# MSS_IOMUX_IOMUX_53100000h register map
Vendor: Texas Instruments
Peripheral module from a debugger description file (folder AM263X).
Registers are 32-bit, read-write, reset values left out (the file's numbers can be read two ways) unless marked. A register's access mark holds for its fields unless they carry their own. Offsets are as the file gives them; lines under a group give offsets from that group; [hi:lo] are bit positions; {n}, {i} and the like mark numbered series; 'fields as' and 'values as' point back to an identical list; <NAME> marks a mode.

## IOMUX
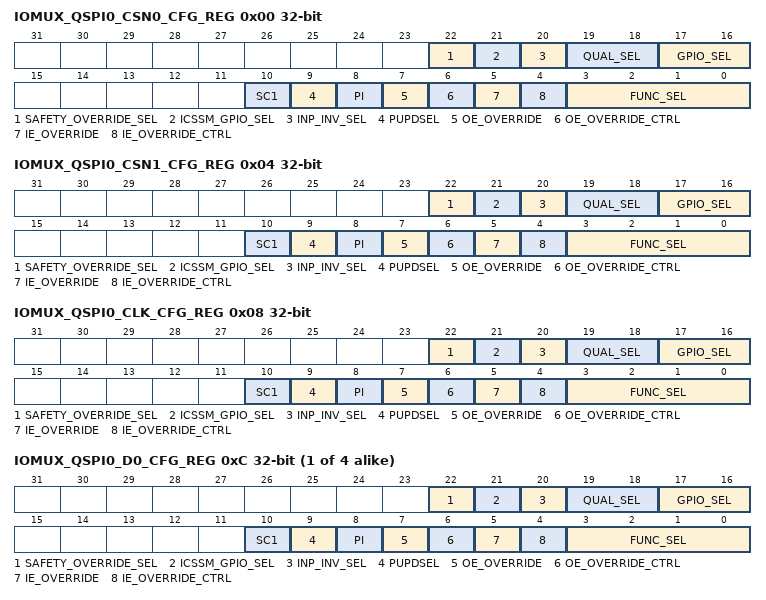
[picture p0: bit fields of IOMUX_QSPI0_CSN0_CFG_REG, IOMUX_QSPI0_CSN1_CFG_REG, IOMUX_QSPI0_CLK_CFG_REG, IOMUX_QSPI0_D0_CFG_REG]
0x00 IOMUX_QSPI0_CSN0_CFG_REG — QSPI0_CSn0 IO config register.
  [22] SAFETY_OVERRIDE_SEL — mux Select Value to choose between Actual IO pad input and Safety override mux output1 Safety override mux output is selected0 Actual IO pad input is selected
  [21] ICSSM_GPIO_SEL — mux Select Value to choose between ICSSM_GPIO and normal GPIO 1 ICSSM_GPIO is selected0 Normal GPIO is selected
  [20] INP_INV_SEL — Select Value for chosing inverted version of PAD input for chip:0 : Non Inverted1 : Inverted
  [19:18] QUAL_SEL — Select Value for chosing input qualifer type for PAD.00 : Sync, 01 : 3 Sample qual 10 : 6 Samples qual 11 : Async
  [17:16] GPIO_SEL — R5F CPU ownership select for GPIO.0 : GPO0, 1 :GPO1,2 : GPO2, 3:GPO3
  [10] SC1 — IO Slew Rate Control :0 : higher slew rate.1:Lower slew rate.
  [9] PUPDSEL — Internal Pull Resistor Direction Control bit0:Pull-down Resistor1:Pull-up Resistor
  [8] PI — Pull Inhibit/Pull Disable 0 -- Enable 1- Disable
  [7] OE_OVERRIDE — Active Low Output Override
  [6] OE_OVERRIDE_CTRL — Output Override Control bit (Active Low)This bit provides a software override for the default OE_N/GZ hardware control.0:Enable pad input override1:Disable pad input override
  [5] IE_OVERRIDE — Input Override (Active Low)0:Override pad input signal to 0 (LOW)1:Override pad input signal to 1 (HIGH)
  [4] IE_OVERRIDE_CTRL — Input Override (Active Low)0:Override pad input signal to 0 (LOW)1:Override pad input signal to 1 (HIGH) Control : Write 1 to select Active low Input Override value to control IOs IE_N/RXACTIVE_N instead of the control from hardware
  [3:0] FUNC_SEL — Function select
0x04 IOMUX_QSPI0_CSN1_CFG_REG — QSPI0_CSn1 IO config register.
  fields as IOMUX_QSPI0_CSN0_CFG_REG
0x08 IOMUX_QSPI0_CLK_CFG_REG — QSPI0_CLK IO config register.
  fields as IOMUX_QSPI0_CSN0_CFG_REG
{0xC+4i} IOMUX_QSPI0_D{i}_CFG_REG (i=0..3) — QSPI0_D{i} IO config register.
  fields as IOMUX_QSPI0_CSN0_CFG_REG
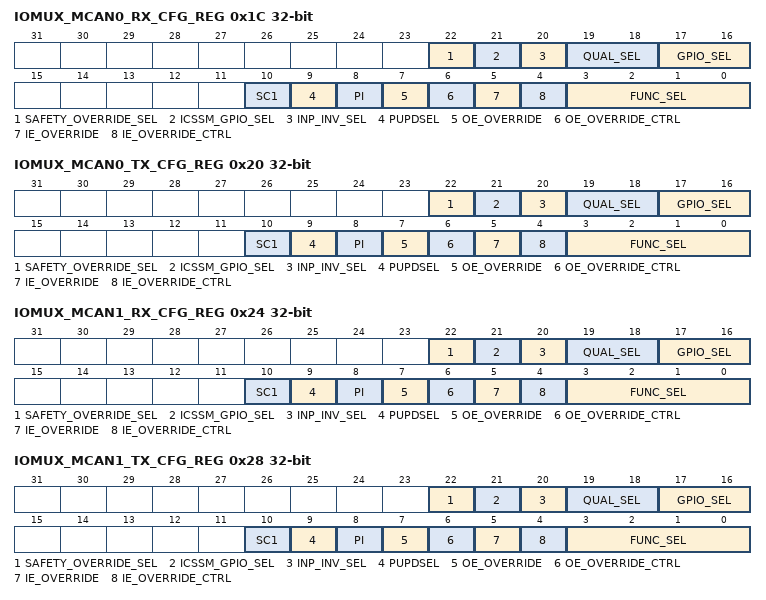
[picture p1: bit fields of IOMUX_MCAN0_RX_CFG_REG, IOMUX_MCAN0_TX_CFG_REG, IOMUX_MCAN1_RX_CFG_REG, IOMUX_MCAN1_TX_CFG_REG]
0x1C IOMUX_MCAN0_RX_CFG_REG — MCAN0_RX IO config register.
  fields as IOMUX_QSPI0_CSN0_CFG_REG
0x20 IOMUX_MCAN0_TX_CFG_REG — MCAN0_TX IO config register.
  fields as IOMUX_QSPI0_CSN0_CFG_REG
0x24 IOMUX_MCAN1_RX_CFG_REG — MCAN1_RX IO config register.
  fields as IOMUX_QSPI0_CSN0_CFG_REG
0x28 IOMUX_MCAN1_TX_CFG_REG — MCAN1_TX IO config register.
  fields as IOMUX_QSPI0_CSN0_CFG_REG
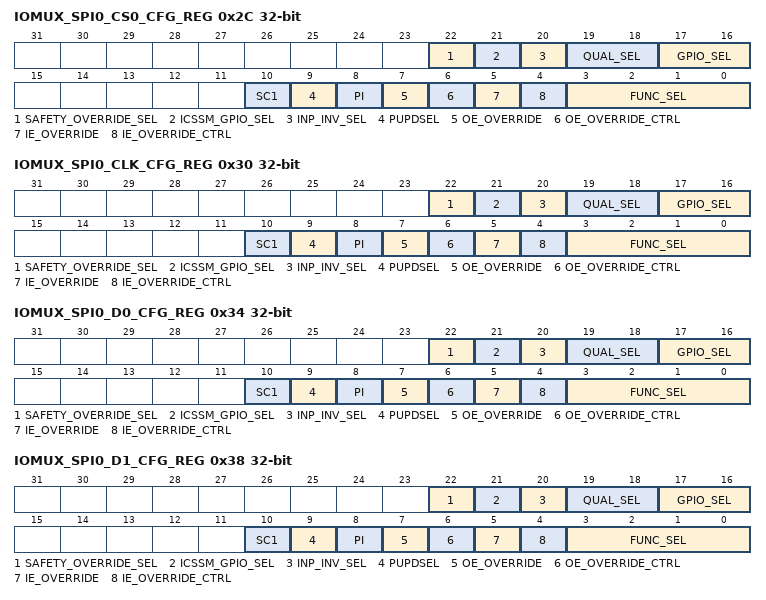
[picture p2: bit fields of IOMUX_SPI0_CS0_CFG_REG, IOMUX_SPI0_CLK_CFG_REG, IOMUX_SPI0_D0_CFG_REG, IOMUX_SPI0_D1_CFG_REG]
0x2C IOMUX_SPI0_CS0_CFG_REG — SPI0_CS0 IO config register.
  fields as IOMUX_QSPI0_CSN0_CFG_REG
0x30 IOMUX_SPI0_CLK_CFG_REG — SPI0_CLK IO config register.
  fields as IOMUX_QSPI0_CSN0_CFG_REG
0x34 IOMUX_SPI0_D0_CFG_REG — SPI0_D0 IO config register.
  fields as IOMUX_QSPI0_CSN0_CFG_REG
0x38 IOMUX_SPI0_D1_CFG_REG — SPI0_D1 IO config register.
  fields as IOMUX_QSPI0_CSN0_CFG_REG
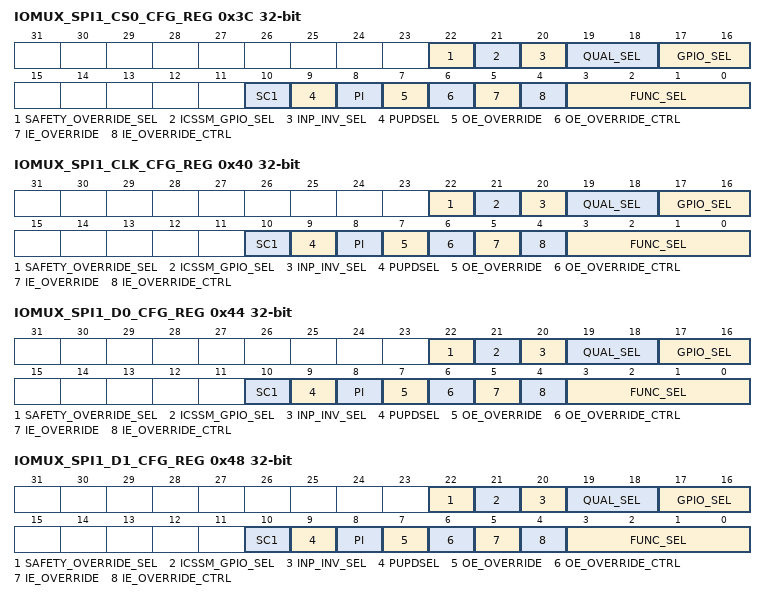
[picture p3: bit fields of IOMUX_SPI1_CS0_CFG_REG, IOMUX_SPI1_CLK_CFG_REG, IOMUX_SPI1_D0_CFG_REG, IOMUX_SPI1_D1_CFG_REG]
0x3C IOMUX_SPI1_CS0_CFG_REG — SPI1_CS0 IO config register.
  fields as IOMUX_QSPI0_CSN0_CFG_REG
0x40 IOMUX_SPI1_CLK_CFG_REG — SPI1_CLK IO config register.
  fields as IOMUX_QSPI0_CSN0_CFG_REG
0x44 IOMUX_SPI1_D0_CFG_REG — SPI1_D0 IO config register.
  fields as IOMUX_QSPI0_CSN0_CFG_REG
0x48 IOMUX_SPI1_D1_CFG_REG — SPI1_D1 IO config register.
  fields as IOMUX_QSPI0_CSN0_CFG_REG
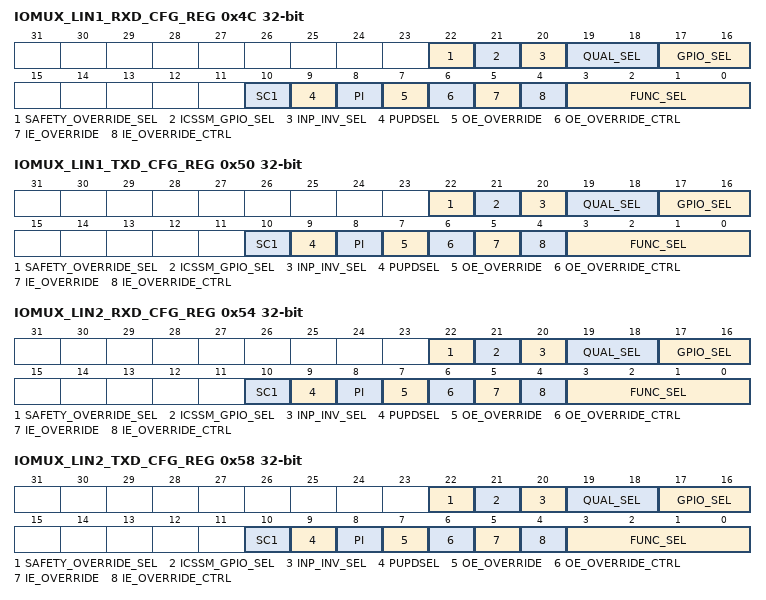
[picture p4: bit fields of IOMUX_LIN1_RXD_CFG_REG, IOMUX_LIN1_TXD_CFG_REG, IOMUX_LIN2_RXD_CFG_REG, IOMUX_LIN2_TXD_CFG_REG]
0x4C IOMUX_LIN1_RXD_CFG_REG — LIN1_RXD IO config register.
  fields as IOMUX_QSPI0_CSN0_CFG_REG
0x50 IOMUX_LIN1_TXD_CFG_REG — LIN1_TXD IO config register.
  fields as IOMUX_QSPI0_CSN0_CFG_REG
0x54 IOMUX_LIN2_RXD_CFG_REG — LIN2_RXD IO config register.
  fields as IOMUX_QSPI0_CSN0_CFG_REG
0x58 IOMUX_LIN2_TXD_CFG_REG — LIN2_TXD IO config register.
  fields as IOMUX_QSPI0_CSN0_CFG_REG
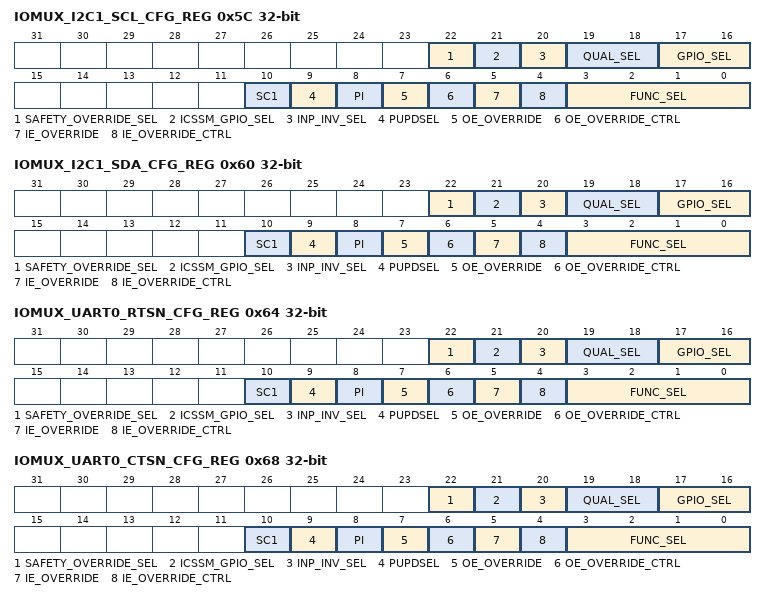
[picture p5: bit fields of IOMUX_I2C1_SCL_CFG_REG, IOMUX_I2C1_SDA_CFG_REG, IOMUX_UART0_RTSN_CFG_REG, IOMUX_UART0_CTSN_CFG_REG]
0x5C IOMUX_I2C1_SCL_CFG_REG — I2C1_SCL IO config register.
  fields as IOMUX_QSPI0_CSN0_CFG_REG
0x60 IOMUX_I2C1_SDA_CFG_REG — I2C1_SDA IO config register.
  fields as IOMUX_QSPI0_CSN0_CFG_REG
0x64 IOMUX_UART0_RTSN_CFG_REG — UART0_RTSn IO config register.
  fields as IOMUX_QSPI0_CSN0_CFG_REG
0x68 IOMUX_UART0_CTSN_CFG_REG — UART0_CTSn IO config register.
  fields as IOMUX_QSPI0_CSN0_CFG_REG
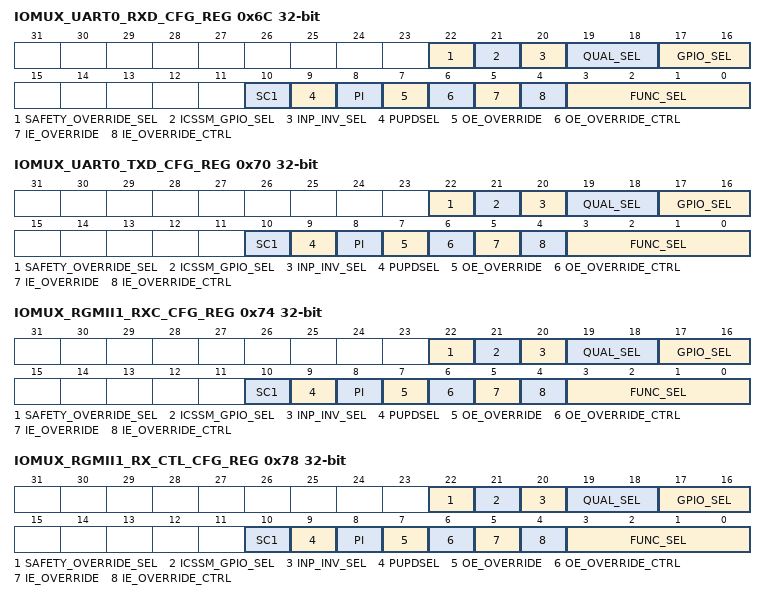
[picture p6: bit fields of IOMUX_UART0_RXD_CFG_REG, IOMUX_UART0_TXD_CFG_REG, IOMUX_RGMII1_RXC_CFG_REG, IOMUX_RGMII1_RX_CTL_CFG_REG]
0x6C IOMUX_UART0_RXD_CFG_REG — UART0_RXD IO config register.
  fields as IOMUX_QSPI0_CSN0_CFG_REG
0x70 IOMUX_UART0_TXD_CFG_REG — UART0_TXD IO config register.
  fields as IOMUX_QSPI0_CSN0_CFG_REG
0x74 IOMUX_RGMII1_RXC_CFG_REG — RGMII1_RXC IO config register.
  fields as IOMUX_QSPI0_CSN0_CFG_REG
0x78 IOMUX_RGMII1_RX_CTL_CFG_REG — RGMII1_RX_CTL IO config register.
  fields as IOMUX_QSPI0_CSN0_CFG_REG
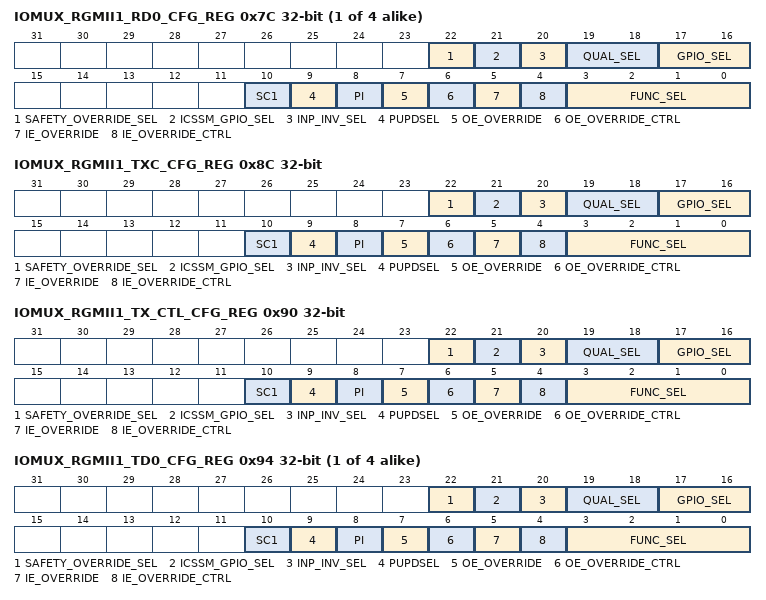
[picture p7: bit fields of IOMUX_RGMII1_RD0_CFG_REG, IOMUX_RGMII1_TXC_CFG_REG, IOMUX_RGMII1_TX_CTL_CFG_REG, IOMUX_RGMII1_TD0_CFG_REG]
{0x7C+4i} IOMUX_RGMII1_RD{i}_CFG_REG (i=0..3) — RGMII1_RD{i} IO config register.
  fields as IOMUX_QSPI0_CSN0_CFG_REG
0x8C IOMUX_RGMII1_TXC_CFG_REG — RGMII1_TXC IO config register.
  fields as IOMUX_QSPI0_CSN0_CFG_REG
0x90 IOMUX_RGMII1_TX_CTL_CFG_REG — RGMII1_TX_CTL IO config register.
  fields as IOMUX_QSPI0_CSN0_CFG_REG
{0x94+4i} IOMUX_RGMII1_TD{i}_CFG_REG (i=0..3) — RGMII1_TD{i} IO config register.
  fields as IOMUX_QSPI0_CSN0_CFG_REG
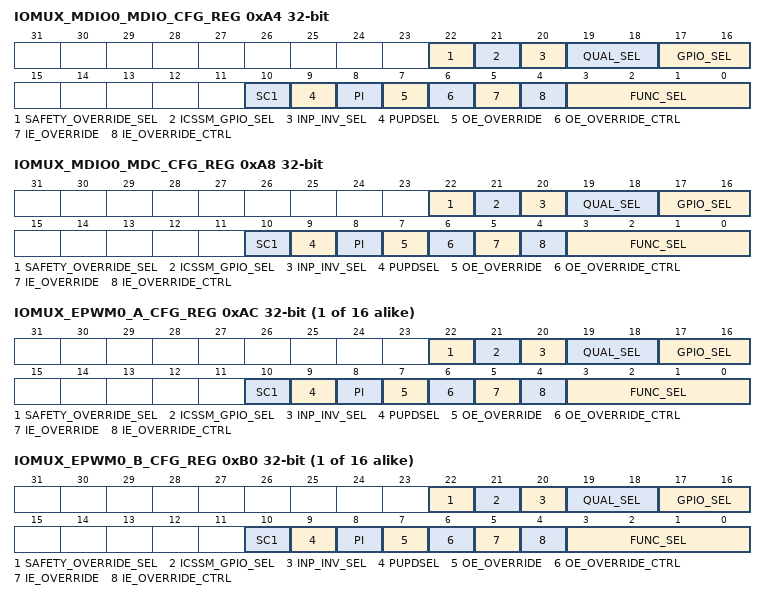
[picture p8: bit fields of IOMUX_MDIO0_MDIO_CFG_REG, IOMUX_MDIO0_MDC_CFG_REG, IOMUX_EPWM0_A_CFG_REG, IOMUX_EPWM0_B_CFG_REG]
0xA4 IOMUX_MDIO0_MDIO_CFG_REG — MDIO0_MDIO IO config register.
  fields as IOMUX_QSPI0_CSN0_CFG_REG
0xA8 IOMUX_MDIO0_MDC_CFG_REG — MDIO0_MDC IO config register.
  fields as IOMUX_QSPI0_CSN0_CFG_REG
{0xAC+8i} IOMUX_EPWM{i}_A_CFG_REG (i=0..15) — EPWM{i}_A IO config register.
  fields as IOMUX_QSPI0_CSN0_CFG_REG
{0xB0+8i} IOMUX_EPWM{i}_B_CFG_REG (i=0..15) — EPWM{i}_B IO config register.
  fields as IOMUX_QSPI0_CSN0_CFG_REG
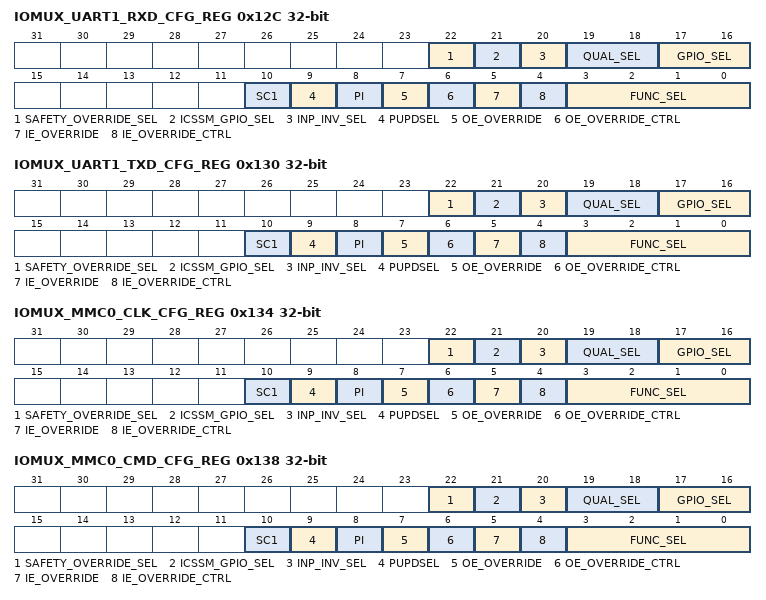
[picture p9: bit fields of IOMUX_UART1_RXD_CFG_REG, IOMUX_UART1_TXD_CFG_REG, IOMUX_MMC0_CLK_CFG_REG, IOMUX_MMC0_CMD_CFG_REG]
0x12C IOMUX_UART1_RXD_CFG_REG — UART1_RXD IO config register.
  fields as IOMUX_QSPI0_CSN0_CFG_REG
0x130 IOMUX_UART1_TXD_CFG_REG — UART1_TXD IO config register.
  fields as IOMUX_QSPI0_CSN0_CFG_REG
0x134 IOMUX_MMC0_CLK_CFG_REG — MMC0_CLK IO config register.
  fields as IOMUX_QSPI0_CSN0_CFG_REG
0x138 IOMUX_MMC0_CMD_CFG_REG — MMC0_CMD IO config register.
  fields as IOMUX_QSPI0_CSN0_CFG_REG
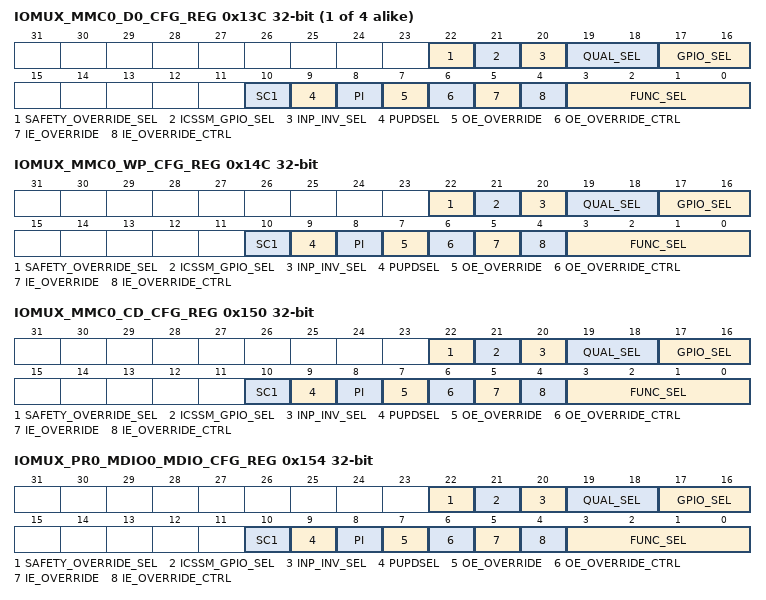
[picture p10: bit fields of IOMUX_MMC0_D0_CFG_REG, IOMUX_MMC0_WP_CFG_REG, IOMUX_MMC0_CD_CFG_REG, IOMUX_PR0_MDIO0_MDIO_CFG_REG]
{0x13C+4i} IOMUX_MMC0_D{i}_CFG_REG (i=0..3) — MMC0_D{i} IO config register.
  fields as IOMUX_QSPI0_CSN0_CFG_REG
0x14C IOMUX_MMC0_WP_CFG_REG — MMC0_WP IO config register.
  fields as IOMUX_QSPI0_CSN0_CFG_REG
0x150 IOMUX_MMC0_CD_CFG_REG — MMC0_CD IO config register.
  fields as IOMUX_QSPI0_CSN0_CFG_REG
0x154 IOMUX_PR0_MDIO0_MDIO_CFG_REG — PR0_MDIO0_MDIO IO config register.
  fields as IOMUX_QSPI0_CSN0_CFG_REG
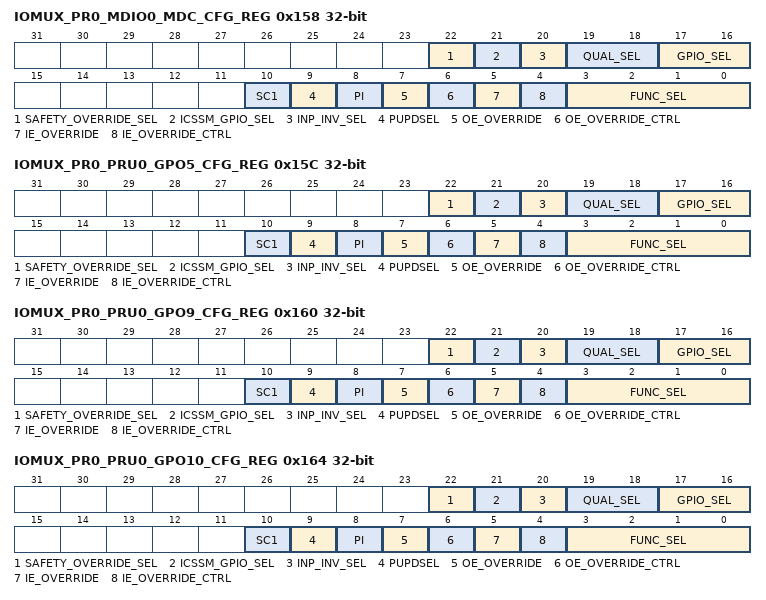
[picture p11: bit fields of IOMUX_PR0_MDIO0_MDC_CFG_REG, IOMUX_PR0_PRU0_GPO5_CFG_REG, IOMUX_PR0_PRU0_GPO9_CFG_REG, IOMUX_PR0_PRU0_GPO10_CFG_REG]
0x158 IOMUX_PR0_MDIO0_MDC_CFG_REG — PR0_MDIO0_MDC IO config register.
  fields as IOMUX_QSPI0_CSN0_CFG_REG
0x15C IOMUX_PR0_PRU0_GPO5_CFG_REG — PR0_PRU0_GPO5 IO config register.
  fields as IOMUX_QSPI0_CSN0_CFG_REG
0x160 IOMUX_PR0_PRU0_GPO9_CFG_REG — PR0_PRU0_GPO9 IO config register.
  fields as IOMUX_QSPI0_CSN0_CFG_REG
0x164 IOMUX_PR0_PRU0_GPO10_CFG_REG — PR0_PRU0_GPO10 IO config register.
  fields as IOMUX_QSPI0_CSN0_CFG_REG
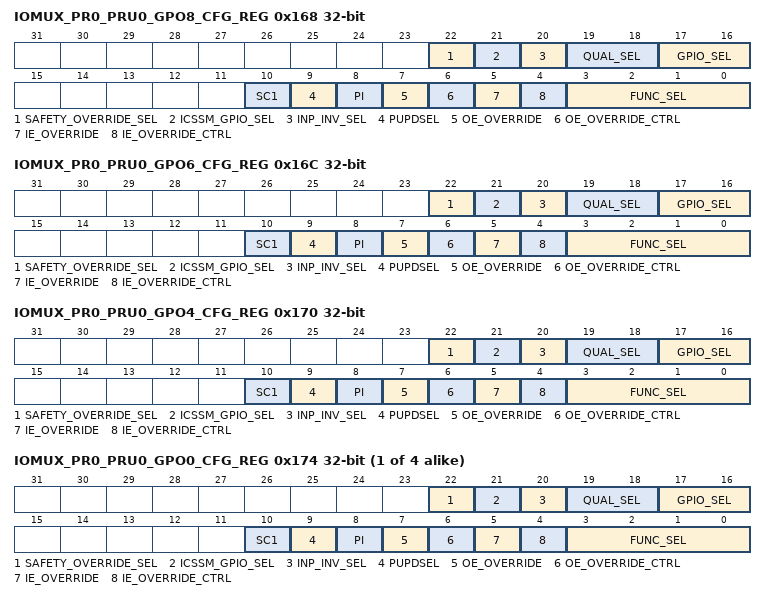
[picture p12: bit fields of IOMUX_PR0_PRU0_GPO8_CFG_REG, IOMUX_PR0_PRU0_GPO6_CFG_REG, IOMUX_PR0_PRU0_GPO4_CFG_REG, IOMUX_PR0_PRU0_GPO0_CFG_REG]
0x168 IOMUX_PR0_PRU0_GPO8_CFG_REG — PR0_PRU0_GPO8 IO config register.
  fields as IOMUX_QSPI0_CSN0_CFG_REG
0x16C IOMUX_PR0_PRU0_GPO6_CFG_REG — PR0_PRU0_GPO6 IO config register.
  fields as IOMUX_QSPI0_CSN0_CFG_REG
0x170 IOMUX_PR0_PRU0_GPO4_CFG_REG — PR0_PRU0_GPO4 IO config register.
  fields as IOMUX_QSPI0_CSN0_CFG_REG
{0x174+4i} IOMUX_PR0_PRU0_GPO{i}_CFG_REG (i=0..3) — PR0_PRU0_GPO{i} IO config register.
  fields as IOMUX_QSPI0_CSN0_CFG_REG
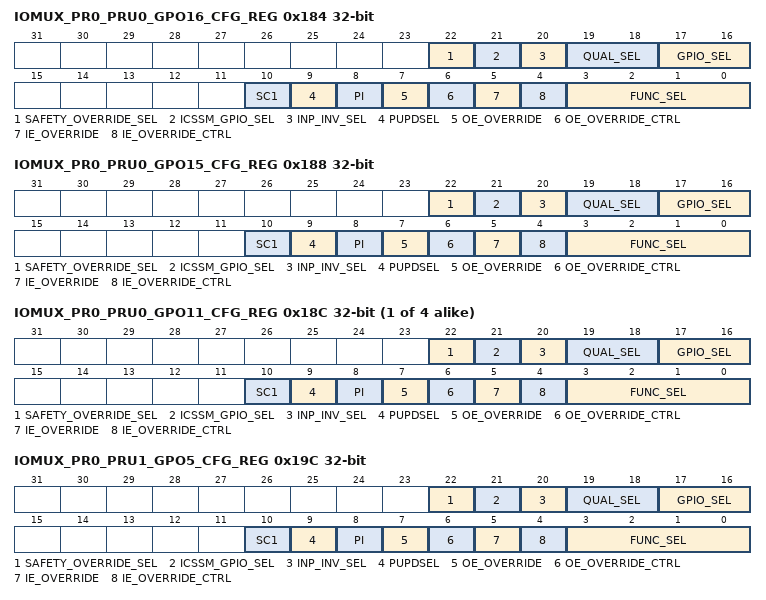
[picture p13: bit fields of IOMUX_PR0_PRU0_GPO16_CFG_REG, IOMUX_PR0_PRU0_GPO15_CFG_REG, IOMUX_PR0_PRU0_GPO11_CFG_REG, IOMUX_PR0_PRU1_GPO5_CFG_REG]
0x184 IOMUX_PR0_PRU0_GPO16_CFG_REG — PR0_PRU0_GPO16 IO config register.
  fields as IOMUX_QSPI0_CSN0_CFG_REG
0x188 IOMUX_PR0_PRU0_GPO15_CFG_REG — PR0_PRU0_GPO15 IO config register.
  fields as IOMUX_QSPI0_CSN0_CFG_REG
{0x160+4i} IOMUX_PR0_PRU0_GPO{i}_CFG_REG (i=11..14) — PR0_PRU0_GPO{i} IO config register.
  fields as IOMUX_QSPI0_CSN0_CFG_REG
0x19C IOMUX_PR0_PRU1_GPO5_CFG_REG — PR0_PRU1_GPO5 IO config register.
  fields as IOMUX_QSPI0_CSN0_CFG_REG
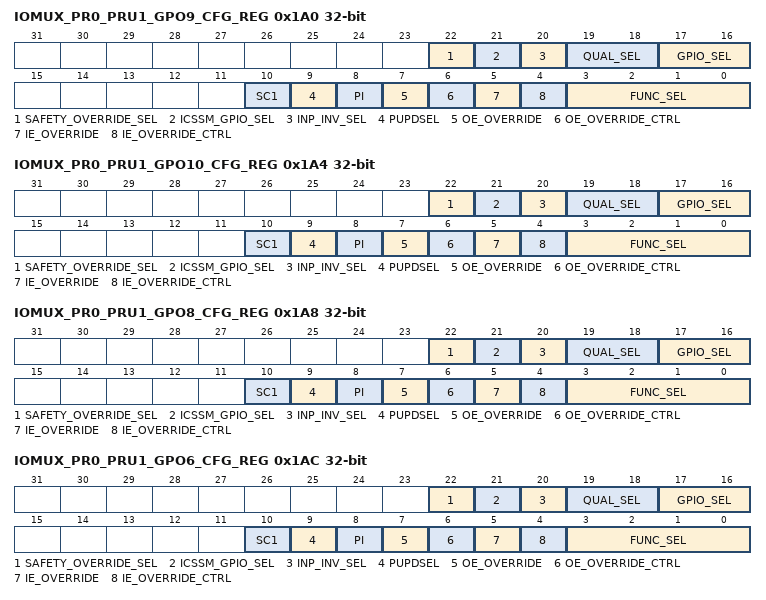
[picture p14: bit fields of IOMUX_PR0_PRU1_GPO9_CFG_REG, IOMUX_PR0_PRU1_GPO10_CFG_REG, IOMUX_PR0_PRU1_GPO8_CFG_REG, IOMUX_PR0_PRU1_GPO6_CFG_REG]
0x1A0 IOMUX_PR0_PRU1_GPO9_CFG_REG — PR0_PRU1_GPO9 IO config register.
  fields as IOMUX_QSPI0_CSN0_CFG_REG
0x1A4 IOMUX_PR0_PRU1_GPO10_CFG_REG — PR0_PRU1_GPO10 IO config register.
  fields as IOMUX_QSPI0_CSN0_CFG_REG
0x1A8 IOMUX_PR0_PRU1_GPO8_CFG_REG — PR0_PRU1_GPO8 IO config register.
  fields as IOMUX_QSPI0_CSN0_CFG_REG
0x1AC IOMUX_PR0_PRU1_GPO6_CFG_REG — PR0_PRU1_GPO6 IO config register.
  fields as IOMUX_QSPI0_CSN0_CFG_REG
0x1B0 IOMUX_PR0_PRU1_GPO4_CFG_REG — PR0_PRU1_GPO4 IO config register.
  fields as IOMUX_QSPI0_CSN0_CFG_REG
{0x1B4+4i} IOMUX_PR0_PRU1_GPO{i}_CFG_REG (i=0..3) — PR0_PRU1_GPO{i} IO config register.
  fields as IOMUX_QSPI0_CSN0_CFG_REG
0x1C4 IOMUX_PR0_PRU1_GPO16_CFG_REG — PR0_PRU1_GPO16 IO config register.
  fields as IOMUX_QSPI0_CSN0_CFG_REG
0x1C8 IOMUX_PR0_PRU1_GPO15_CFG_REG — PR0_PRU1_GPO15 IO config register.
  fields as IOMUX_QSPI0_CSN0_CFG_REG
{0x1A0+4i} IOMUX_PR0_PRU1_GPO{i}_CFG_REG (i=11..14) — PR0_PRU1_GPO{i} IO config register.
  fields as IOMUX_QSPI0_CSN0_CFG_REG
0x1DC IOMUX_PR0_PRU1_GPO19_CFG_REG — PR0_PRU1_GPO19 IO config register.
  fields as IOMUX_QSPI0_CSN0_CFG_REG
0x1E0 IOMUX_PR0_PRU1_GPO18_CFG_REG — PR0_PRU1_GPO18 IO config register.
  fields as IOMUX_QSPI0_CSN0_CFG_REG
0x1E4 IOMUX_EXT_REFCLK0_CFG_REG — EXT_REFCLK0 IO config register.
  fields as IOMUX_QSPI0_CSN0_CFG_REG
{0x1E8+8i} IOMUX_SDFM0_CLK{i}_CFG_REG (i=0..3) — SDFM0_CLK{i} IO config register.
  fields as IOMUX_QSPI0_CSN0_CFG_REG
{0x1EC+8i} IOMUX_SDFM0_D{i}_CFG_REG (i=0..3) — SDFM0_D{i} IO config register.
  fields as IOMUX_QSPI0_CSN0_CFG_REG
0x208 IOMUX_EQEP0_A_CFG_REG — EQEP0_A IO config register.
  fields as IOMUX_QSPI0_CSN0_CFG_REG
0x20C IOMUX_EQEP0_B_CFG_REG — EQEP0_B IO config register.
  fields as IOMUX_QSPI0_CSN0_CFG_REG
0x210 IOMUX_EQEP0_STROBE_CFG_REG — EQEP0_STROBE IO config register.
  fields as IOMUX_QSPI0_CSN0_CFG_REG
0x214 IOMUX_EQEP0_INDEX_CFG_REG — EQEP0_INDEX IO config register.
  fields as IOMUX_QSPI0_CSN0_CFG_REG
0x218 IOMUX_I2C0_SDA_CFG_REG — I2C0_SDA IO config register.
  fields as IOMUX_QSPI0_CSN0_CFG_REG
0x21C IOMUX_I2C0_SCL_CFG_REG — I2C0_SCL IO config register.
  fields as IOMUX_QSPI0_CSN0_CFG_REG
0x220 IOMUX_MCAN2_TX_CFG_REG — MCAN2_TX IO config register.
  fields as IOMUX_QSPI0_CSN0_CFG_REG
0x224 IOMUX_MCAN2_RX_CFG_REG — MCAN2_RX IO config register.
  fields as IOMUX_QSPI0_CSN0_CFG_REG
0x228 IOMUX_CLKOUT0_CFG_REG — CLKOUT0 IO config register.
  fields as IOMUX_QSPI0_CSN0_CFG_REG
0x22C IOMUX_WARMRSTN_CFG_REG — WARMRSTn IO config register.
  [10] SC1 — IO Slew Rate Control :0 : higher slew rate.1:Lower slew rate.
  [9] PUPDSEL — Internal Pull Resistor Direction Control bit0:Pull-down Resistor1:Pull-up Resistor
  [8] PI — Pull Inhibit/Pull Disable 0 -- Enable 1- Disable
  [7] OE_OVERRIDE — Active Low Output Override
  [6] OE_OVERRIDE_CTRL — Output Override Control bit (Active Low)This bit provides a software override for the default OE_N/GZ hardware control.0:Enable pad input override1:Disable pad input override
  [5] IE_OVERRIDE — Input Override (Active Low)0:Override pad input signal to 0 (LOW)1:Override pad input signal to 1 (HIGH)
  [4] IE_OVERRIDE_CTRL — Input Override (Active Low)0:Override pad input signal to 0 (LOW)1:Override pad input signal to 1 (HIGH) Control : Write 1 to select Active low Input Override value to control IOs IE_N/RXACTIVE_N instead of the control from hardware
0x230 IOMUX_SAFETY_ERRORN_CFG_REG — SAFETY_ERRORn IO config register.
  fields as IOMUX_WARMRSTN_CFG_REG
0x234 IOMUX_TDI_CFG_REG — TDI IO config register.
  fields as IOMUX_WARMRSTN_CFG_REG
0x238 IOMUX_TDO_CFG_REG — TDO IO config register.
  fields as IOMUX_WARMRSTN_CFG_REG
0x23C IOMUX_TMS_CFG_REG — TMS IO config register.
  fields as IOMUX_WARMRSTN_CFG_REG
0x240 IOMUX_TCK_CFG_REG — TCK IO config register.
  fields as IOMUX_WARMRSTN_CFG_REG
0x244 IOMUX_OSPI0_CLKLB_CFG_REG — OSPI0_CLKLB IO config register.
  fields as IOMUX_WARMRSTN_CFG_REG
{0x248+4i} IOMUX_QUAL_GRP_{i}_CFG_REG (i=0..17) — QUAL_GRP_{i} config register.
  [7:0] QUAL_PERIOD_PER_SAMPLE — MMR bits for programming the qualifier clock count per sample
0x290 IOMUX_USER_MODE_EN — USER_MODE_EN config register.
  [31:0] USER_MODE_EN — Write 0XADADADAD to enable user mode write access to IO CFG space
0x294 IOMUX_PADGLBL_CFG_REG — Global config register for IO.
  [31:0] PADGLBL_CFG_REG — 20 : global_ie_n_ctl - Write 3'b111 to pass global_ie_n_val to IE_N/RXACTIVE_N pin of all the IOs.3 : global_ie_n_val - Active low108 : global_oe_n_ctl - Write 3'b111 to pass global_oe_n_val to OE_N/GZ pin of all the IOs.11 : global_oe_n_val - Active low1816 : global_pi_ctl - Write 3'b111 to pass global_pi_val and global_pu_val to all the IOs19 : global_pi_val20 : global_pu_val
0x298 IOMUX_IO_CFG_KICK0 — KICK0 config register.
  [31:0] IO_CFG_KICK0 — Kicker 0 Register. The value 83E7 0B13h must be written to KICK0 as part of the process to unlock the CPU.write access to the above PIN MUX registers [including IOCFGKICK1]
0x29C IOMUX_IO_CFG_KICK1 — KICK1 config register.
  [31:0] IO_CFG_KICK1 — Kicker 1 Register. The value 95A4 F1E0h must be written to the KICK1 as part of the process to unlock the CPU write access to above PINMUX registers [excluding IOCFGKICK0]. IOCFGKICK0 has to be written with 83E70B13h to enable access to IOCFGKICK1.
